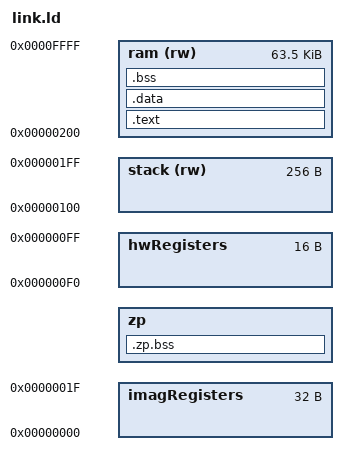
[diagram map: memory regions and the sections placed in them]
MEMORY {
    imagRegisters : ORIGIN = 0x00, LENGTH = 0x20
    zp : ORIGIN = __rc31 + 1, LENGTH = 0x0F0 - (__rc31 + 1)
    hwRegisters : ORIGIN = 0xF0, LENGTH = 0x10
    stack (rw) : ORIGIN = 0x100, LENGTH = 0x0100
    ram (rw) : ORIGIN = 0x200, LENGTH = 0xFE00
}

REGION_ALIAS("c_readonly", ram)
REGION_ALIAS("c_writeable", ram)

SECTIONS {
    .zp.bss (NOLOAD) : { *(.zp.bss .zp.bss.* .zp.data .zp.data.* .zp.rodata .zp.rodata.*) } > zp

    .text : {
        *(.text*)
        *(.rodata*)
    } > ram

    .data : {
        *(.data*)
    } > ram

    .bss (NOLOAD) : {
        *(.bss*)
        *(COMMON)
    } > ram
}

__stack = 0xFFC0;

__rc0 = 0x00;
INCLUDE imag-regs.ld
ASSERT(__rc0 == 0x00, "Inconsistent zero page map.")
ASSERT(__rc31 == 0x1f, "Inconsistent zero page map.")

OUTPUT_FORMAT {
  /* SPC file header — exactly 256 bytes */
  BYTE(83) BYTE(78) BYTE(69) BYTE(83) BYTE(45)
  BYTE(83) BYTE(80) BYTE(67) BYTE(55) BYTE(48) BYTE(48)
  BYTE(32)
  BYTE(83) BYTE(111) BYTE(117) BYTE(110) BYTE(100) BYTE(32)
  BYTE(70) BYTE(105) BYTE(108) BYTE(101) BYTE(32)
  BYTE(68) BYTE(97) BYTE(116) BYTE(97) BYTE(32)
  BYTE(118) BYTE(48) BYTE(46) BYTE(51) BYTE(48)
  BYTE(26) BYTE(26) BYTE(27) BYTE(30)
  SHORT(_start)
  BYTE(0) BYTE(0) BYTE(0) BYTE(0) BYTE(0xEF)
  BYTE(0) BYTE(0)
  BYTE(0) BYTE(0) BYTE(0) BYTE(0) BYTE(0) BYTE(0) BYTE(0) BYTE(0) BYTE(0) BYTE(0) BYTE(0) BYTE(0) BYTE(0) BYTE(0) BYTE(0) BYTE(0)
  BYTE(0) BYTE(0) BYTE(0) BYTE(0) BYTE(0) BYTE(0) BYTE(0) BYTE(0) BYTE(0) BYTE(0) BYTE(0) BYTE(0) BYTE(0) BYTE(0) BYTE(0) BYTE(0)
  BYTE(0) BYTE(0) BYTE(0) BYTE(0) BYTE(0) BYTE(0) BYTE(0) BYTE(0) BYTE(0) BYTE(0) BYTE(0) BYTE(0) BYTE(0) BYTE(0) BYTE(0) BYTE(0)
  BYTE(0) BYTE(0) BYTE(0) BYTE(0) BYTE(0) BYTE(0) BYTE(0) BYTE(0) BYTE(0) BYTE(0) BYTE(0) BYTE(0) BYTE(0) BYTE(0) BYTE(0) BYTE(0)
  BYTE(0) BYTE(0) BYTE(0) BYTE(0) BYTE(0) BYTE(0) BYTE(0) BYTE(0) BYTE(0) BYTE(0) BYTE(0) BYTE(0) BYTE(0) BYTE(0) BYTE(0) BYTE(0)
  BYTE(0) BYTE(0) BYTE(0) BYTE(0) BYTE(0) BYTE(0) BYTE(0) BYTE(0) BYTE(0) BYTE(0) BYTE(0) BYTE(0) BYTE(0) BYTE(0) BYTE(0) BYTE(0)
  BYTE(0) BYTE(0) BYTE(0) BYTE(0) BYTE(0) BYTE(0) BYTE(0) BYTE(0) BYTE(0) BYTE(0) BYTE(0) BYTE(0) BYTE(0) BYTE(0) BYTE(0) BYTE(0)
  BYTE(0) BYTE(0) BYTE(0) BYTE(0) BYTE(0) BYTE(0) BYTE(0) BYTE(0) BYTE(0) BYTE(0) BYTE(0) BYTE(0) BYTE(0) BYTE(0) BYTE(0) BYTE(0)
  BYTE(0) BYTE(0) BYTE(0) BYTE(0) BYTE(0) BYTE(0) BYTE(0) BYTE(0) BYTE(0) BYTE(0) BYTE(0) BYTE(0) BYTE(0) BYTE(0) BYTE(0) BYTE(0)
  BYTE(0) BYTE(0) BYTE(0) BYTE(0) BYTE(0) BYTE(0) BYTE(0) BYTE(0) BYTE(0) BYTE(0) BYTE(0) BYTE(0) BYTE(0) BYTE(0) BYTE(0) BYTE(0)
  BYTE(0) BYTE(0) BYTE(0) BYTE(0) BYTE(0) BYTE(0) BYTE(0) BYTE(0) BYTE(0) BYTE(0) BYTE(0) BYTE(0) BYTE(0) BYTE(0) BYTE(0) BYTE(0)
  BYTE(0) BYTE(0) BYTE(0) BYTE(0) BYTE(0) BYTE(0) BYTE(0) BYTE(0) BYTE(0) BYTE(0) BYTE(0) BYTE(0) BYTE(0) BYTE(0) BYTE(0) BYTE(0)
  BYTE(0) BYTE(0) BYTE(0) BYTE(0) BYTE(0) BYTE(0) BYTE(0) BYTE(0) BYTE(0) BYTE(0) BYTE(0) BYTE(0) BYTE(0) BYTE(0) BYTE(0) BYTE(0)
  BYTE(0) BYTE(0)

  /* SPC700 ROM image */
  FULL(imagRegisters)
  FULL(zp)
  FULL(hwRegisters)
  FULL(stack)
  FULL(ram)

  /* DSP registers at SPC offset 0x10100 — FLG=0x20 disables echo */
  BYTE(0) BYTE(0) BYTE(0) BYTE(0) BYTE(0) BYTE(0) BYTE(0) BYTE(0) BYTE(0) BYTE(0) BYTE(0) BYTE(0) BYTE(0) BYTE(0) BYTE(0) BYTE(0)
  BYTE(0) BYTE(0) BYTE(0) BYTE(0) BYTE(0) BYTE(0) BYTE(0) BYTE(0) BYTE(0) BYTE(0) BYTE(0) BYTE(0) BYTE(0) BYTE(0) BYTE(0) BYTE(0)
  BYTE(0) BYTE(0) BYTE(0) BYTE(0) BYTE(0) BYTE(0) BYTE(0) BYTE(0) BYTE(0) BYTE(0) BYTE(0) BYTE(0) BYTE(0) BYTE(0) BYTE(0) BYTE(0)
  BYTE(0) BYTE(0) BYTE(0) BYTE(0) BYTE(0) BYTE(0) BYTE(0) BYTE(0) BYTE(0) BYTE(0) BYTE(0) BYTE(0) BYTE(0) BYTE(0) BYTE(0) BYTE(0)
  BYTE(0) BYTE(0) BYTE(0) BYTE(0) BYTE(0) BYTE(0) BYTE(0) BYTE(0) BYTE(0) BYTE(0) BYTE(0) BYTE(0) BYTE(0) BYTE(0) BYTE(0) BYTE(0)
  BYTE(0) BYTE(0) BYTE(0) BYTE(0) BYTE(0) BYTE(0) BYTE(0) BYTE(0) BYTE(0) BYTE(0) BYTE(0) BYTE(0) BYTE(0x20) BYTE(0) BYTE(0) BYTE(0)
  BYTE(0) BYTE(0) BYTE(0) BYTE(0) BYTE(0) BYTE(0) BYTE(0) BYTE(0) BYTE(0) BYTE(0) BYTE(0) BYTE(0) BYTE(0) BYTE(0) BYTE(0) BYTE(0)
  BYTE(0) BYTE(0) BYTE(0) BYTE(0) BYTE(0) BYTE(0) BYTE(0) BYTE(0) BYTE(0) BYTE(0) BYTE(0) BYTE(0) BYTE(0) BYTE(0) BYTE(0) BYTE(0)
}
